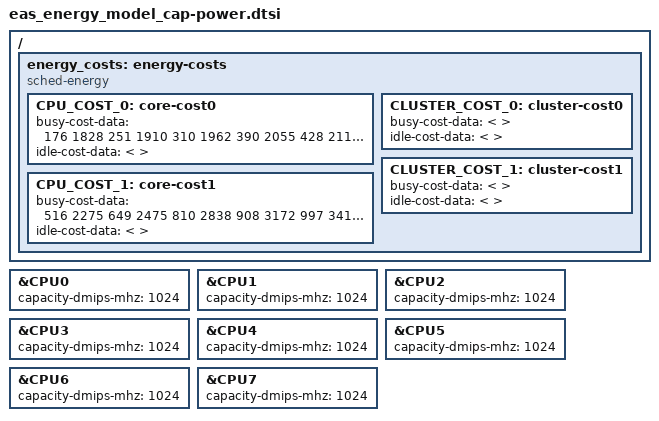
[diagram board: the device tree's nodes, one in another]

&CPU0 {
	capacity-dmips-mhz = <1024>;
};

&CPU1 {
	capacity-dmips-mhz = <1024>;
};

&CPU2 {
	capacity-dmips-mhz = <1024>;
};

&CPU3 {
	capacity-dmips-mhz = <1024>;
};

&CPU4 {
	capacity-dmips-mhz = <1024>;
};

&CPU5 {
	capacity-dmips-mhz = <1024>;
};

&CPU6 {
	capacity-dmips-mhz = <1024>;
};

&CPU7 {
	capacity-dmips-mhz = <1024>;
};

/ {
	energy_costs: energy-costs {
		compatible = "sched-energy";

		CPU_COST_0: core-cost0 {
			busy-cost-data = <
				 176 1828
				 251 1910
				 310 1962
				 390 2055
				 428 2112
				 487 2222
				 513 2266
			>;
			idle-cost-data = <
				
			>;
		};

		CPU_COST_1: core-cost1 {
			busy-cost-data = <
				 516 2275
				 649 2475
				 810 2838
				 908 3172
				 997 3410
				1024 3696
			>;
			idle-cost-data = <
				
			>;
		};

		CLUSTER_COST_0: cluster-cost0 {
			busy-cost-data = <
			>;
			idle-cost-data = <
				
			>;
		};

		CLUSTER_COST_1: cluster-cost1 {
			busy-cost-data = <
			>;
			idle-cost-data = <
				
			>;
		};
	}; /* energy-costs */
};
